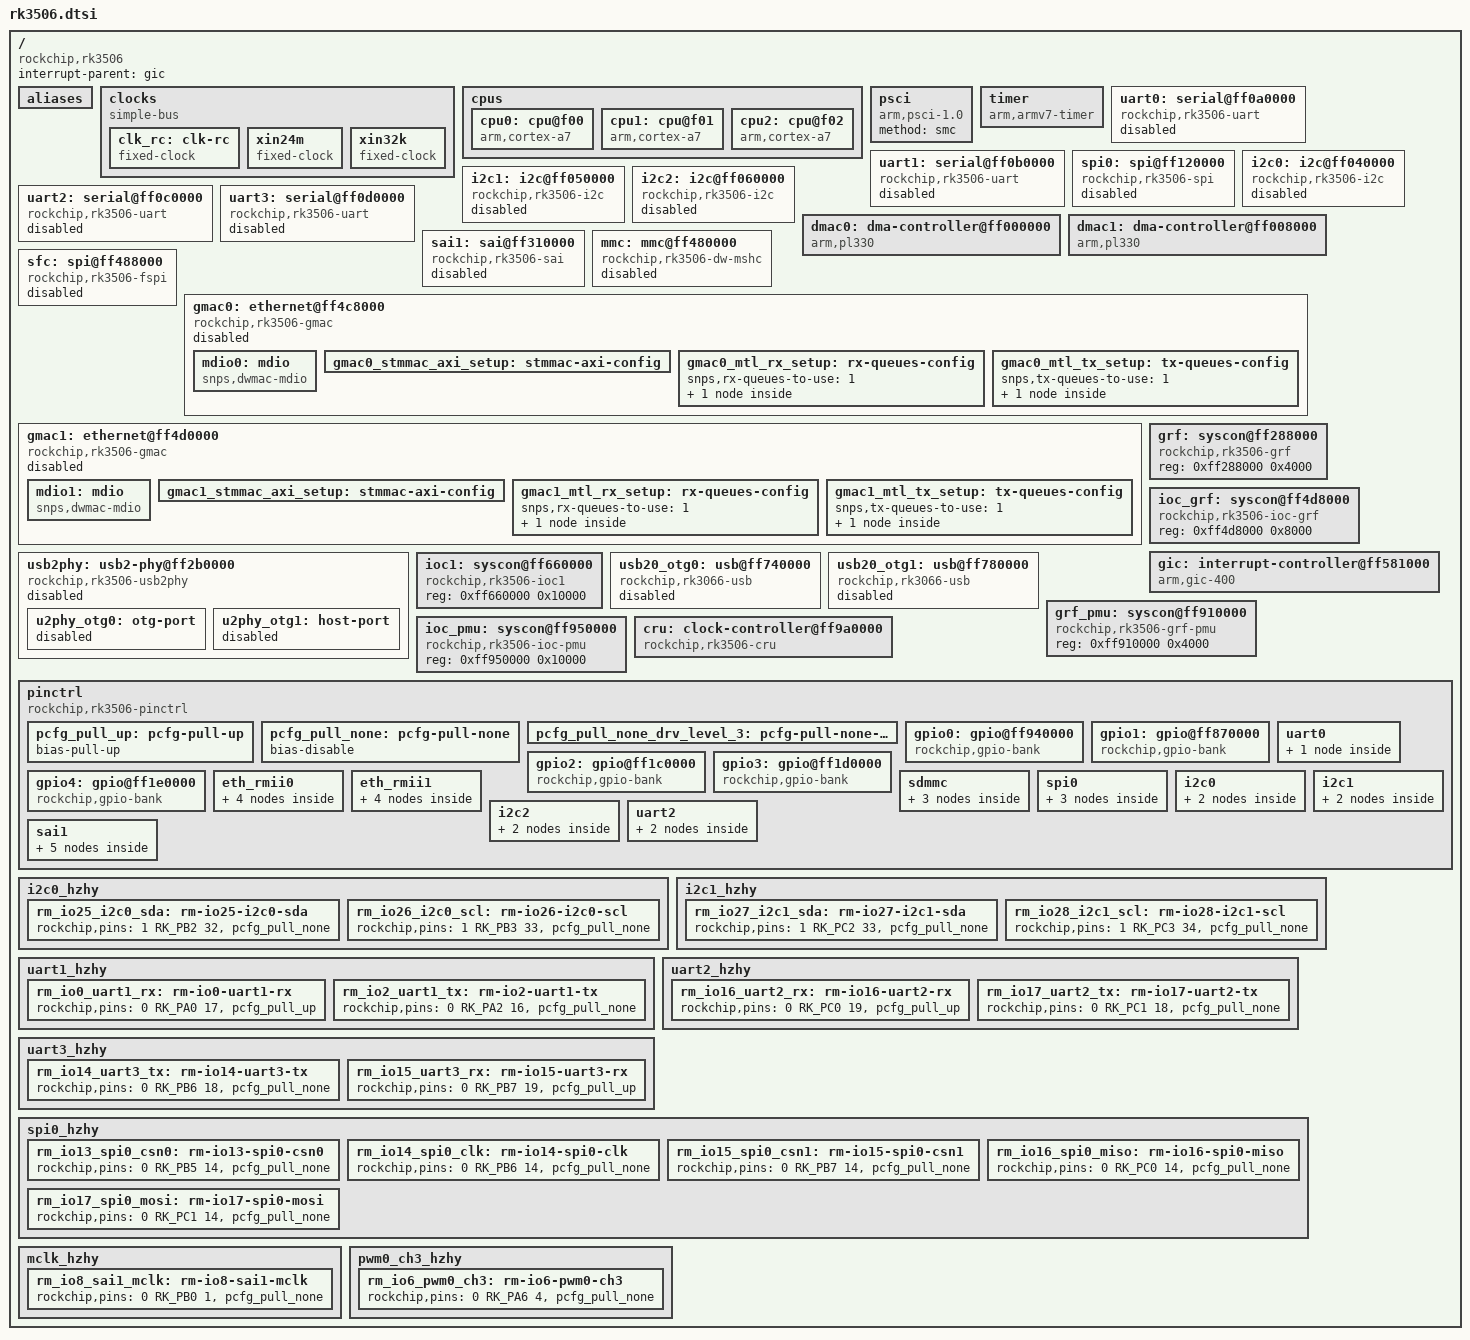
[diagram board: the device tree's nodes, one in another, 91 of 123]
// SPDX-License-Identifier: (GPL-2.0+ OR MIT)
/*
 * (C) Copyright 2023 Rockchip Electronics Co., Ltd.
 *
 * Minimal RK3506 SoC dtsi for mainline Linux bring-up.
 * Ported/reduced from the ATK vendor SDK rk3502.dtsi. Nodes needed to boot +
 * reach the early UART console: clocks, cru, grf, ioc syscons, gic, arch timer,
 * psci, cpus, pinctrl (all 5 gpio banks) + uart0.
 * + sfc (SPI flash controller) — drives the W25N04KV SPI-NAND, needed for a
 *   persistent rootfs on NAND. Uses the mainline `rockchip,sfc` binding (the
 *   same node proven on the U-Boot side); vendor BSP instead uses a private
 *   `fspi` driver — we stay mainline. The mainline rockchip_sfc.c now ports
 *   the vendor delay-line tuning, so the SFC runs at full speed. See notes/10
 *   + BLOBS.md.
 * Other peripherals (i2c/spi/pwm/sai/mmc/usb/display/io-domains) still deferred.
 */

#include <dt-bindings/clock/rockchip,rk3506-cru.h>
#include <dt-bindings/reset/rockchip,rk3506-cru.h>
#include <dt-bindings/gpio/gpio.h>
#include <dt-bindings/interrupt-controller/irq.h>
#include <dt-bindings/interrupt-controller/arm-gic.h>
#include <dt-bindings/pinctrl/rockchip.h>

/ {
	#address-cells = <1>;
	#size-cells = <1>;

	compatible = "rockchip,rk3506";

	interrupt-parent = <&gic>;

	aliases {
		gpio0 = &gpio0;
		gpio1 = &gpio1;
		gpio2 = &gpio2;
		gpio3 = &gpio3;
		gpio4 = &gpio4;
		serial0 = &uart0;
		serial2 = &uart2;
		ethernet0 = &gmac0;
		ethernet1 = &gmac1;
		i2c0 = &i2c0;
		i2c1 = &i2c1;
		i2c2 = &i2c2;
	};

	clocks {
		compatible = "simple-bus";
		#address-cells = <1>;
		#size-cells = <1>;
		ranges;

		clk_rc: clk-rc {
			compatible = "fixed-clock";
			#clock-cells = <0>;
			clock-frequency = <400000>;
			clock-output-names = "clk_rc";
		};

		xin24m: xin24m {
			compatible = "fixed-clock";
			#clock-cells = <0>;
			clock-frequency = <24000000>;
			clock-output-names = "xin24m";
		};

		xin32k: xin32k {
			compatible = "fixed-clock";
			#clock-cells = <0>;
			clock-frequency = <32768>;
			clock-output-names = "xin32k";
		};
	};

	cpus {
		#address-cells = <1>;
		#size-cells = <0>;

		cpu0: cpu@f00 {
			device_type = "cpu";
			compatible = "arm,cortex-a7";
			reg = <0xf00>;
			enable-method = "psci";
			clocks = <&cru ARMCLK>;
		};

		cpu1: cpu@f01 {
			device_type = "cpu";
			compatible = "arm,cortex-a7";
			reg = <0xf01>;
			enable-method = "psci";
			clocks = <&cru ARMCLK>;
		};

		cpu2: cpu@f02 {
			device_type = "cpu";
			compatible = "arm,cortex-a7";
			reg = <0xf02>;
			enable-method = "psci";
			clocks = <&cru ARMCLK>;
		};
	};

	psci {
		compatible = "arm,psci-1.0";
		method = "smc";
	};

	timer {
		compatible = "arm,armv7-timer";
		interrupts = <GIC_PPI 13 (GIC_CPU_MASK_SIMPLE(3) | IRQ_TYPE_LEVEL_HIGH)>,
			     <GIC_PPI 14 (GIC_CPU_MASK_SIMPLE(3) | IRQ_TYPE_LEVEL_HIGH)>,
			     <GIC_PPI 11 (GIC_CPU_MASK_SIMPLE(3) | IRQ_TYPE_LEVEL_HIGH)>,
			     <GIC_PPI 10 (GIC_CPU_MASK_SIMPLE(3) | IRQ_TYPE_LEVEL_HIGH)>;
		clock-frequency = <24000000>;
	};

	uart0: serial@ff0a0000 {
		compatible = "rockchip,rk3506-uart", "snps,dw-apb-uart";
		reg = <0xff0a0000 0x100>;
		interrupts = <GIC_SPI 34 IRQ_TYPE_LEVEL_HIGH>;
		reg-shift = <2>;
		reg-io-width = <4>;
		clocks = <&cru SCLK_UART0>, <&cru PCLK_UART0>;
		clock-names = "baudclk", "apb_pclk";
		pinctrl-names = "default";
		pinctrl-0 = <&uart0_xfer_pins>;
		status = "disabled";
	};
	uart1: serial@ff0b0000 {
		compatible = "rockchip,rk3506-uart", "snps,dw-apb-uart";
		reg = <0xff0b0000 0x100>;
		interrupts = <GIC_SPI 35 IRQ_TYPE_LEVEL_HIGH>;
		reg-shift = <2>;
		reg-io-width = <4>;
		clocks = <&cru SCLK_UART1>, <&cru PCLK_UART1>;
		clock-names = "baudclk", "apb_pclk";
		pinctrl-names = "default";
		status = "disabled";
	};


	spi0: spi@ff120000 {
		compatible = "rockchip,rk3506-spi", "rockchip,rk3066-spi";
		reg = <0xff120000 0x1000>;
		interrupts = <GIC_SPI 43 IRQ_TYPE_LEVEL_HIGH>;
		#address-cells = <1>;
		#size-cells = <0>;
		clocks = <&cru CLK_SPI0>, <&cru PCLK_SPI0>;
		clock-names = "spiclk", "apb_pclk";
		num-cs = <2>;
		pinctrl-names = "default";
		pinctrl-0 = <&spi0_csn0_pins &spi0_csn1_pins &spi0_clk_pins>;
		status = "disabled";
	};

	i2c0: i2c@ff040000 {
		compatible = "rockchip,rk3506-i2c", "rockchip,rk3399-i2c";
		reg = <0xff040000 0x1000>;
		interrupts = <GIC_SPI 40 IRQ_TYPE_LEVEL_HIGH>;
		#address-cells = <1>;
		#size-cells = <0>;
		clocks = <&cru CLK_I2C0>, <&cru PCLK_I2C0>;
		clock-names = "i2c", "pclk";
		status = "disabled";
	};

	i2c1: i2c@ff050000 {
		compatible = "rockchip,rk3506-i2c", "rockchip,rk3399-i2c";
		reg = <0xff050000 0x1000>;
		interrupts = <GIC_SPI 41 IRQ_TYPE_LEVEL_HIGH>;
		#address-cells = <1>;
		#size-cells = <0>;
		clocks = <&cru CLK_I2C1>, <&cru PCLK_I2C1>;
		clock-names = "i2c", "pclk";
		status = "disabled";
	};

	i2c2: i2c@ff060000 {
		compatible = "rockchip,rk3506-i2c", "rockchip,rk3399-i2c";
		reg = <0xff060000 0x1000>;
		interrupts = <GIC_SPI 42 IRQ_TYPE_LEVEL_HIGH>;
		#address-cells = <1>;
		#size-cells = <0>;
		clocks = <&cru CLK_I2C2>, <&cru PCLK_I2C2>;
		clock-names = "i2c", "pclk";
		status = "disabled";
	};

	uart2: serial@ff0c0000 {
		compatible = "rockchip,rk3506-uart", "snps,dw-apb-uart";
		reg = <0xff0c0000 0x100>;
		interrupts = <GIC_SPI 36 IRQ_TYPE_LEVEL_HIGH>;
		reg-shift = <2>;
		reg-io-width = <4>;
		clocks = <&cru SCLK_UART2>, <&cru PCLK_UART2>;
		clock-names = "baudclk", "apb_pclk";
		status = "disabled";
	};

	uart3: serial@ff0d0000 {
		compatible = "rockchip,rk3506-uart", "snps,dw-apb-uart";
		reg = <0xff0d0000 0x100>;
		interrupts = <GIC_SPI 37 IRQ_TYPE_LEVEL_HIGH>;
		reg-shift = <2>;
		reg-io-width = <4>;
		clocks = <&cru SCLK_UART3>, <&cru PCLK_UART3>;
		clock-names = "baudclk", "apb_pclk";
		pinctrl-names = "default";
		status = "disabled";
	};

	dmac0: dma-controller@ff000000 {
		compatible = "arm,pl330", "arm,primecell";
		reg = <0xff000000 0x4000>;
		interrupts = <GIC_SPI 116 IRQ_TYPE_LEVEL_HIGH>,
			     <GIC_SPI 117 IRQ_TYPE_LEVEL_HIGH>;
		clocks = <&cru ACLK_DMAC0>;
		clock-names = "apb_pclk";
		#dma-cells = <5>;
		arm,pl330-periph-burst;
	};

	dmac1: dma-controller@ff008000 {
		compatible = "arm,pl330", "arm,primecell";
		reg = <0xff008000 0x4000>;
		interrupts = <GIC_SPI 118 IRQ_TYPE_LEVEL_HIGH>,
			     <GIC_SPI 119 IRQ_TYPE_LEVEL_HIGH>;
		clocks = <&cru ACLK_DMAC1>;
		clock-names = "apb_pclk";
		#dma-cells = <5>;
		arm,pl330-periph-burst;
	};

	sai1: sai@ff310000 {
		compatible = "rockchip,rk3506-sai", "rockchip,sai-v1";
		reg = <0xff310000 0x1000>;
		interrupts = <GIC_SPI 51 IRQ_TYPE_LEVEL_HIGH>;
		clocks = <&cru MCLK_SAI1>, <&cru HCLK_SAI1>;
		clock-names = "mclk", "hclk";
		/* 5-cell: <dmac chan mux_reg mux_val mux_reg mux_val> — the GRF
		 * DMA request crossbar (programmed by the pl330 dmamux patch). */
		dmas = <&dmac1 3  0xff2880a4 0x04000000 0x0 0x0>,
		       <&dmac1 2  0xff2880a4 0x02000000 0x0 0x0>;
		dma-names = "tx", "rx";
		resets = <&cru SRST_M_SAI1>, <&cru SRST_H_SAI1>;
		reset-names = "m", "h";
		#sound-dai-cells = <0>;
		pinctrl-names = "default";
		/* sdo0 only (stereo) — sdo1/2/3 would clash with i2c0 on PB5/6/7. */
		pinctrl-0 = <&sai1_lrck_pins &sai1_sclk_pins &sai1_sdi_pins
			     &sai1_sdo0_pins &sai1_mclk_pins>;
		status = "disabled";
	};

	mmc: mmc@ff480000 {
		compatible = "rockchip,rk3506-dw-mshc", "rockchip,rk3288-dw-mshc";
		reg = <0xff480000 0x4000>;
		interrupts = <GIC_SPI 86 IRQ_TYPE_LEVEL_HIGH>;
		max-frequency = <150000000>;
		bus-width = <4>;
		clocks = <&cru HCLK_SDMMC>, <&cru CCLK_SRC_SDMMC>;
		clock-names = "biu", "ciu";
		fifo-depth = <0x100>;
		resets = <&cru SRST_H_SDMMC>;
		reset-names = "reset";
		status = "disabled";
	};

	sfc: spi@ff488000 {
		compatible = "rockchip,rk3506-fspi", "rockchip,sfc";
		reg = <0xff488000 0x4000>;
		interrupts = <GIC_SPI 85 IRQ_TYPE_LEVEL_HIGH>;
		clocks = <&cru SCLK_FSPI>, <&cru HCLK_FSPI>;
		clock-names = "clk_sfc", "hclk_sfc";
		rockchip,grf = <&grf_pmu>;	/* power-good gate (GRF_PMU+0x100 bit0); needed for reliable writes */
		/* No rockchip,sfc-no-dma → use DMA (aligns vendor rk3506 fspi, which has no no-dma).
		 * The earlier no-dma was a stale debug workaround (nand-ecc-debug-handoff, "rule out
		 * DMA/cache"); "DMA reads corrupt" was never proven. NB: DMA does NOT fix the
		 * rootfs PEB-3/4 -74 — that's loader marginal write (~8flips, read-nondeterministic),
		 * handled by ubiprog (notes/27). DMA kept purely for vendor parity. */
		rockchip,max-dll = <0x17F>;	/* RK3506 SFC is VER_5; cap DLL cell scan (vendor value) */
		#address-cells = <1>;
		#size-cells = <0>;
		status = "disabled";
	};

	gmac0: ethernet@ff4c8000 {
		compatible = "rockchip,rk3506-gmac", "snps,dwmac-4.20a";
		reg = <0xff4c8000 0x2000>;
		interrupts = <GIC_SPI 66 IRQ_TYPE_LEVEL_HIGH>,
			     <GIC_SPI 69 IRQ_TYPE_LEVEL_HIGH>;
		interrupt-names = "macirq", "eth_wake_irq";
		rockchip,grf = <&grf>;
		clocks = <&cru CLK_MAC0>, <&cru CLK_MAC0_PTP>,
			 <&cru PCLK_MAC0>, <&cru ACLK_MAC0>;
		clock-names = "stmmaceth", "ptp_ref",
			      "pclk_mac", "aclk_mac";
		resets = <&cru SRST_A_MAC0>;
		reset-names = "stmmaceth";

		assigned-clocks = <&cru CLK_MAC0_PTP>;
		assigned-clock-rates = <62500000>;

		snps,mixed-burst;
		snps,tso;

		snps,axi-config = <&gmac0_stmmac_axi_setup>;
		snps,mtl-rx-config = <&gmac0_mtl_rx_setup>;
		snps,mtl-tx-config = <&gmac0_mtl_tx_setup>;

		phy-mode = "rmii";
		status = "disabled";

		mdio0: mdio {
			compatible = "snps,dwmac-mdio";
			#address-cells = <0x1>;
			#size-cells = <0x0>;
		};

		gmac0_stmmac_axi_setup: stmmac-axi-config {
			snps,wr_osr_lmt = <4>;
			snps,rd_osr_lmt = <8>;
			snps,blen = <0 0 0 0 16 8 4>;
		};

		gmac0_mtl_rx_setup: rx-queues-config {
			snps,rx-queues-to-use = <1>;
			queue0 {
				status = "okay";
			};
		};

		gmac0_mtl_tx_setup: tx-queues-config {
			snps,tx-queues-to-use = <1>;
			queue0 {
				status = "okay";
			};
		};
	};

	gmac1: ethernet@ff4d0000 {
		compatible = "rockchip,rk3506-gmac", "snps,dwmac-4.20a";
		reg = <0xff4d0000 0x2000>;
		interrupts = <GIC_SPI 70 IRQ_TYPE_LEVEL_HIGH>,
			     <GIC_SPI 73 IRQ_TYPE_LEVEL_HIGH>;
		interrupt-names = "macirq", "eth_wake_irq";
		rockchip,grf = <&grf>;
		clocks = <&cru CLK_MAC1>, <&cru CLK_MAC1_PTP>,
			 <&cru PCLK_MAC1>, <&cru ACLK_MAC1>;
		clock-names = "stmmaceth", "ptp_ref",
			      "pclk_mac", "aclk_mac";
		resets = <&cru SRST_A_MAC1>;
		reset-names = "stmmaceth";

		assigned-clocks = <&cru CLK_MAC1_PTP>;
		assigned-clock-rates = <62500000>;

		snps,mixed-burst;
		snps,tso;

		snps,axi-config = <&gmac1_stmmac_axi_setup>;
		snps,mtl-rx-config = <&gmac1_mtl_rx_setup>;
		snps,mtl-tx-config = <&gmac1_mtl_tx_setup>;

		phy-mode = "rmii";
		status = "disabled";

		mdio1: mdio {
			compatible = "snps,dwmac-mdio";
			#address-cells = <0x1>;
			#size-cells = <0x0>;
		};

		gmac1_stmmac_axi_setup: stmmac-axi-config {
			snps,wr_osr_lmt = <4>;
			snps,rd_osr_lmt = <8>;
			snps,blen = <0 0 0 0 16 8 4>;
		};

		gmac1_mtl_rx_setup: rx-queues-config {
			snps,rx-queues-to-use = <1>;
			queue0 {
				status = "okay";
			};
		};

		gmac1_mtl_tx_setup: tx-queues-config {
			snps,tx-queues-to-use = <1>;
			queue0 {
				status = "okay";
			};
		};
	};

	grf: syscon@ff288000 {
		compatible = "rockchip,rk3506-grf", "syscon", "simple-mfd";
		reg = <0xff288000 0x4000>;
	};

	usb2phy: usb2-phy@ff2b0000 {
		compatible = "rockchip,rk3506-usb2phy";
		reg = <0xff2b0000 0x8000>;
		clocks = <&cru CLK_REF_USBPHY_TOP>, <&cru PCLK_USBPHY>;
		clock-names = "phyclk", "apb_pclk";
		rockchip,usbgrf = <&grf>;
		status = "disabled";

		u2phy_otg0: otg-port {
			#phy-cells = <0>;
			interrupts = <GIC_SPI 75 IRQ_TYPE_LEVEL_HIGH>,
				     <GIC_SPI 76 IRQ_TYPE_LEVEL_HIGH>,
				     <GIC_SPI 77 IRQ_TYPE_LEVEL_HIGH>;
			interrupt-names = "otg-bvalid", "otg-id", "linestate";
			status = "disabled";
		};

		u2phy_otg1: host-port {
			#phy-cells = <0>;
			interrupts = <GIC_SPI 80 IRQ_TYPE_LEVEL_HIGH>,
				     <GIC_SPI 81 IRQ_TYPE_LEVEL_HIGH>,
				     <GIC_SPI 82 IRQ_TYPE_LEVEL_HIGH>;
			interrupt-names = "otg-bvalid", "otg-id", "linestate";
			status = "disabled";
		};
	};

	ioc_grf: syscon@ff4d8000 {
		compatible = "rockchip,rk3506-ioc-grf", "syscon";
		reg = <0xff4d8000 0x8000>;
	};

	gic: interrupt-controller@ff581000 {
		compatible = "arm,gic-400";
		reg = <0xff581000 0x1000>,
		      <0xff582000 0x2000>,
		      <0xff584000 0x2000>,
		      <0xff586000 0x2000>;
		interrupts = <GIC_PPI 9 IRQ_TYPE_LEVEL_HIGH>;
		#interrupt-cells = <3>;
		interrupt-controller;
		#address-cells = <0>;
	};

	ioc1: syscon@ff660000 {
		compatible = "rockchip,rk3506-ioc1", "syscon";
		reg = <0xff660000 0x10000>;
	};

	usb20_otg0: usb@ff740000 {
		compatible = "rockchip,rk3066-usb", "snps,dwc2";
		reg = <0xff740000 0x40000>;
		interrupts = <GIC_SPI 74 IRQ_TYPE_LEVEL_HIGH>;
		clocks = <&cru HCLK_USBOTG0>, <&cru HCLK_USBOTG0_PMU>,
			 <&cru CLK_USBOTG0_ADP>;
		clock-names = "otg", "pmu", "adp";
		dr_mode = "otg";
		phys = <&u2phy_otg0>;
		phy-names = "usb2-phy";
		g-np-tx-fifo-size = <16>;
		g-rx-fifo-size = <280>;
		g-tx-fifo-size = <256 128 128 64 32 16>;
		status = "disabled";
	};

	usb20_otg1: usb@ff780000 {
		compatible = "rockchip,rk3066-usb", "snps,dwc2";
		reg = <0xff780000 0x40000>;
		interrupts = <GIC_SPI 79 IRQ_TYPE_LEVEL_HIGH>;
		clocks = <&cru HCLK_USBOTG1>, <&cru HCLK_USBOTG1_PMU>,
			 <&cru CLK_USBOTG1_ADP>;
		clock-names = "otg", "pmu", "adp";
		dr_mode = "otg";
		phys = <&u2phy_otg1>;
		phy-names = "usb2-phy";
		g-np-tx-fifo-size = <16>;
		g-rx-fifo-size = <280>;
		g-tx-fifo-size = <256 128 128 64 32 16>;
		status = "disabled";
	};

	grf_pmu: syscon@ff910000 {
		compatible = "rockchip,rk3506-grf-pmu", "syscon", "simple-mfd";
		reg = <0xff910000 0x4000>;
	};

	ioc_pmu: syscon@ff950000 {
		compatible = "rockchip,rk3506-ioc-pmu", "syscon";
		reg = <0xff950000 0x10000>;
	};

	cru: clock-controller@ff9a0000 {
		compatible = "rockchip,rk3506-cru";
		reg = <0xff9a0000 0x20000>;
		rockchip,grf = <&grf>;
		#clock-cells = <1>;
		#reset-cells = <1>;

		assigned-clocks =
			<&cru CLK_32K_FRAC>,
			<&cru CLK_FRAC_UART_MATRIX0>,
			<&cru CLK_FRAC_UART_MATRIX1>;
		assigned-clock-rates =
			<32768>,
			<96000000>,
			<128000000>;
	};

	pinctrl: pinctrl {
		compatible = "rockchip,rk3506-pinctrl";
		rockchip,grf = <&ioc_grf>;
		rockchip,ioc1 = <&ioc1>;
		rockchip,pmu = <&ioc_pmu>;
		rockchip,rmio = <&grf_pmu>;	/* RMIO crossbar (rk3506 rm_io pads); see pinctrl RMIO patch */
		#address-cells = <1>;
		#size-cells = <1>;
		ranges;

		pcfg_pull_up: pcfg-pull-up {
			bias-pull-up;
		};

		pcfg_pull_none: pcfg-pull-none {
			bias-disable;
		};

		pcfg_pull_none_drv_level_3: pcfg-pull-none-drv-level-3 {
			bias-disable;
			drive-strength = <3>;
		};

		gpio0: gpio@ff940000 {
			compatible = "rockchip,gpio-bank";
			reg = <0xff940000 0x200>;
			interrupts = <GIC_SPI 0 IRQ_TYPE_LEVEL_HIGH>,
				     <GIC_SPI 1 IRQ_TYPE_LEVEL_HIGH>,
				     <GIC_SPI 2 IRQ_TYPE_LEVEL_HIGH>,
				     <GIC_SPI 3 IRQ_TYPE_LEVEL_HIGH>;
			clocks = <&cru PCLK_GPIO0>, <&cru DBCLK_GPIO0>;

			gpio-controller;
			#gpio-cells = <2>;
			gpio-ranges = <&pinctrl 0 0 32>;
			interrupt-controller;
			#interrupt-cells = <2>;
		};

		gpio1: gpio@ff870000 {
			compatible = "rockchip,gpio-bank";
			reg = <0xff870000 0x200>;
			interrupts = <GIC_SPI 4 IRQ_TYPE_LEVEL_HIGH>,
				     <GIC_SPI 5 IRQ_TYPE_LEVEL_HIGH>,
				     <GIC_SPI 6 IRQ_TYPE_LEVEL_HIGH>,
				     <GIC_SPI 7 IRQ_TYPE_LEVEL_HIGH>;

			clocks = <&cru PCLK_GPIO1>, <&cru DBCLK_GPIO1>;

			gpio-controller;
			#gpio-cells = <2>;
			gpio-ranges = <&pinctrl 0 32 32>;
			interrupt-controller;
			#interrupt-cells = <2>;
		};

		gpio2: gpio@ff1c0000 {
			compatible = "rockchip,gpio-bank";
			reg = <0xff1c0000 0x200>;
			interrupts = <GIC_SPI 8 IRQ_TYPE_LEVEL_HIGH>,
				     <GIC_SPI 9 IRQ_TYPE_LEVEL_HIGH>,
				     <GIC_SPI 10 IRQ_TYPE_LEVEL_HIGH>,
				     <GIC_SPI 11 IRQ_TYPE_LEVEL_HIGH>;
			clocks = <&cru PCLK_GPIO2>, <&cru DBCLK_GPIO2>;

			gpio-controller;
			#gpio-cells = <2>;
			gpio-ranges = <&pinctrl 0 64 32>;
			interrupt-controller;
			#interrupt-cells = <2>;
		};

		gpio3: gpio@ff1d0000 {
			compatible = "rockchip,gpio-bank";
			reg = <0xff1d0000 0x200>;
			interrupts = <GIC_SPI 12 IRQ_TYPE_LEVEL_HIGH>,
				     <GIC_SPI 13 IRQ_TYPE_LEVEL_HIGH>,
				     <GIC_SPI 14 IRQ_TYPE_LEVEL_HIGH>,
				     <GIC_SPI 15 IRQ_TYPE_LEVEL_HIGH>;
			clocks = <&cru PCLK_GPIO3>, <&cru DBCLK_GPIO3>;

			gpio-controller;
			#gpio-cells = <2>;
			gpio-ranges = <&pinctrl 0 96 32>;
			interrupt-controller;
			#interrupt-cells = <2>;
		};

		gpio4: gpio@ff1e0000 {
			compatible = "rockchip,gpio-bank";
			reg = <0xff1e0000 0x200>;
			interrupts = <GIC_SPI 16 IRQ_TYPE_LEVEL_HIGH>,
				     <GIC_SPI 17 IRQ_TYPE_LEVEL_HIGH>,
				     <GIC_SPI 18 IRQ_TYPE_LEVEL_HIGH>,
				     <GIC_SPI 19 IRQ_TYPE_LEVEL_HIGH>;
			clocks = <&cru PCLK_GPIO4>, <&cru DBCLK_GPIO4>;

			gpio-controller;
			#gpio-cells = <2>;
			gpio-ranges = <&pinctrl 0 128 32>;
			interrupt-controller;
			#interrupt-cells = <2>;
		};

		uart0 {
			uart0_xfer_pins: uart0-xfer-pins {
				rockchip,pins =
					/* uart0_rx */ <0 RK_PC7 1 &pcfg_pull_up>,
					/* uart0_tx */ <0 RK_PC6 1 &pcfg_pull_up>;
			};
		};

		eth_rmii0 {
			/omit-if-no-ref/
			eth_rmii0_miim_pins: eth-rmii0-miim-pins {
				rockchip,pins =
					/* eth_rmii0_mdc */ <2 RK_PB6 1 &pcfg_pull_none>,
					/* eth_rmii0_mdio */ <2 RK_PB7 1 &pcfg_pull_none>;
			};

			/omit-if-no-ref/
			eth_rmii0_rx_bus2_pins: eth-rmii0-rx-bus2-pins {
				rockchip,pins =
					/* eth_rmii0_rxd0 */ <2 RK_PB0 1 &pcfg_pull_none>,
					/* eth_rmii0_rxd1 */ <2 RK_PB1 1 &pcfg_pull_none>,
					/* eth_rmii0_rxdvcrs */ <2 RK_PC0 1 &pcfg_pull_none>;
			};

			/omit-if-no-ref/
			eth_rmii0_tx_bus2_pins: eth-rmii0-tx-bus2-pins {
				rockchip,pins =
					/* eth_rmii0_txd0 */ <2 RK_PB3 1 &pcfg_pull_none>,
					/* eth_rmii0_txd1 */ <2 RK_PB4 1 &pcfg_pull_none>,
					/* eth_rmii0_txen */ <2 RK_PB5 1 &pcfg_pull_none>;
			};

			/omit-if-no-ref/
			eth_rmii0_clk_pins: eth-rmii0-clk-pins {
				rockchip,pins =
					/* eth_rmii0_clk */ <2 RK_PB2 1 &pcfg_pull_none>;
			};
		};

		eth_rmii1 {
			/omit-if-no-ref/
			eth_rmii1_miim_pins: eth-rmii1-miim-pins {
				rockchip,pins =
					/* eth_rmii1_mdc */ <3 RK_PB4 2 &pcfg_pull_none>,
					/* eth_rmii1_mdio */ <3 RK_PB5 2 &pcfg_pull_none>;
			};

			/omit-if-no-ref/
			eth_rmii1_rx_bus2_pins: eth-rmii1-rx-bus2-pins {
				rockchip,pins =
					/* eth_rmii1_rxd0 */ <3 RK_PA6 2 &pcfg_pull_none>,
					/* eth_rmii1_rxd1 */ <3 RK_PA7 2 &pcfg_pull_none>,
					/* eth_rmii1_rxdvcrs */ <3 RK_PB6 2 &pcfg_pull_none>;
			};

			/omit-if-no-ref/
			eth_rmii1_tx_bus2_pins: eth-rmii1-tx-bus2-pins {
				rockchip,pins =
					/* eth_rmii1_txd0 */ <3 RK_PB1 2 &pcfg_pull_none>,
					/* eth_rmii1_txd1 */ <3 RK_PB2 2 &pcfg_pull_none>,
					/* eth_rmii1_txen */ <3 RK_PB3 2 &pcfg_pull_none>;
			};

			/omit-if-no-ref/
			eth_rmii1_clk_pins: eth-rmii1-clk-pins {
				rockchip,pins =
					/* eth_rmii1_clk */ <3 RK_PB0 2 &pcfg_pull_none>;
			};
		};

		sdmmc {
			/omit-if-no-ref/
			sdmmc_bus4_pins: sdmmc-bus4-pins {
				rockchip,pins =
					/* sdmmc_d0 */ <3 RK_PA2 1 &pcfg_pull_up>,
					/* sdmmc_d1 */ <3 RK_PA3 1 &pcfg_pull_up>,
					/* sdmmc_d2 */ <3 RK_PA4 1 &pcfg_pull_up>,
					/* sdmmc_d3 */ <3 RK_PA5 1 &pcfg_pull_up>;
			};

			/omit-if-no-ref/
			sdmmc_clk_pins: sdmmc-clk-pins {
				rockchip,pins =
					/* sdmmc_clk */ <3 RK_PA0 1 &pcfg_pull_none>;
			};

			/omit-if-no-ref/
			sdmmc_cmd_pins: sdmmc-cmd-pins {
				rockchip,pins =
					/* sdmmc_cmd */ <3 RK_PA1 1 &pcfg_pull_up>;
			};
		};

		spi0 {
			/omit-if-no-ref/
			spi0_clk_pins: spi0-clk-pins {
				rockchip,pins =
					/* spi0_clk */ <0 RK_PC0 2 &pcfg_pull_none_drv_level_3>,
					/* spi0_miso */ <0 RK_PC2 2 &pcfg_pull_none_drv_level_3>,
					/* spi0_mosi */ <0 RK_PC1 2 &pcfg_pull_none_drv_level_3>;
			};

			/omit-if-no-ref/
			spi0_csn0_pins: spi0-csn0-pins {
				rockchip,pins =
					/* spi0_csn0 */ <0 RK_PC3 2 &pcfg_pull_none_drv_level_3>;
			};

			/omit-if-no-ref/
			spi0_csn1_pins: spi0-csn1-pins {
				rockchip,pins =
					/* spi0_csn1 */ <0 RK_PB7 2 &pcfg_pull_none_drv_level_3>;
			};
		};

		/* RMIO crossbar groups (mux values > iomux width route via grf_pmu).
		 * Reduced from vendor rk3506-pinctrl-rmio.dtsi to the pads the AES
		 * board actually wires: i2c0 on rm_io13/14, i2c1 on rm_io24/25,
		 * i2c2 on rm_io4/5, uart2 on rm_io26/27. */
		i2c0 {
			/omit-if-no-ref/
			rm_io13_i2c0_scl: rm-io13-i2c0-scl {
				rockchip,pins = <0 RK_PB5 30 &pcfg_pull_none>;
			};
			/omit-if-no-ref/
			rm_io14_i2c0_sda: rm-io14-i2c0-sda {
				rockchip,pins = <0 RK_PB6 31 &pcfg_pull_none>;
			};
		};

		i2c1 {
			/omit-if-no-ref/
			rm_io24_i2c1_scl: rm-io24-i2c1-scl {
				rockchip,pins = <1 RK_PB1 32 &pcfg_pull_none>;
			};
			/omit-if-no-ref/
			rm_io25_i2c1_sda: rm-io25-i2c1-sda {
				rockchip,pins = <1 RK_PB2 33 &pcfg_pull_none>;
			};
		};

		i2c2 {
			/omit-if-no-ref/
			rm_io4_i2c2_scl: rm-io4-i2c2-scl {
				rockchip,pins = <0 RK_PA4 34 &pcfg_pull_none>;
			};
			/omit-if-no-ref/
			rm_io5_i2c2_sda: rm-io5-i2c2-sda {
				rockchip,pins = <0 RK_PA5 35 &pcfg_pull_none>;
			};
		};

		uart2 {
			/omit-if-no-ref/
			rm_io26_uart2_tx: rm-io26-uart2-tx {
				rockchip,pins = <1 RK_PB3 18 &pcfg_pull_none>;
			};
			/omit-if-no-ref/
			rm_io27_uart2_rx: rm-io27-uart2-rx {
				rockchip,pins = <1 RK_PC2 19 &pcfg_pull_up>;
			};
		};

		sai1 {
			/omit-if-no-ref/
			sai1_mclk_pins: sai1-mclk-pins {
				rockchip,pins = <0 RK_PB0 1 &pcfg_pull_none>;
			};
			/omit-if-no-ref/
			sai1_sclk_pins: sai1-sclk-pins {
				rockchip,pins = <0 RK_PB1 1 &pcfg_pull_none>;
			};
			/omit-if-no-ref/
			sai1_lrck_pins: sai1-lrck-pins {
				rockchip,pins = <0 RK_PB2 1 &pcfg_pull_none>;
			};
			/omit-if-no-ref/
			sai1_sdi_pins: sai1-sdi-pins {
				rockchip,pins = <0 RK_PB3 1 &pcfg_pull_none>;
			};
			/omit-if-no-ref/
			sai1_sdo0_pins: sai1-sdo0-pins {
				rockchip,pins = <0 RK_PB4 1 &pcfg_pull_none>;
			};
		};
	};
		/*
		 * HZHY MiniEVM RMIO pin groups — additional mappings beyond the
		 * AES reference set. /omit-if-no-ref/ guarded; no conflict with
		 * existing groups (different pad/function combinations).
		 */
		i2c0_hzhy {
			/omit-if-no-ref/
			rm_io25_i2c0_sda: rm-io25-i2c0-sda {
				rockchip,pins = <1 RK_PB2 32 &pcfg_pull_none>;
			};
			/omit-if-no-ref/
			rm_io26_i2c0_scl: rm-io26-i2c0-scl {
				rockchip,pins = <1 RK_PB3 33 &pcfg_pull_none>;
			};
		};
		i2c1_hzhy {
			/omit-if-no-ref/
			rm_io27_i2c1_sda: rm-io27-i2c1-sda {
				rockchip,pins = <1 RK_PC2 33 &pcfg_pull_none>;
			};
			/omit-if-no-ref/
			rm_io28_i2c1_scl: rm-io28-i2c1-scl {
				rockchip,pins = <1 RK_PC3 34 &pcfg_pull_none>;
			};
		};
		uart1_hzhy {
			/omit-if-no-ref/
			rm_io0_uart1_rx: rm-io0-uart1-rx {
				rockchip,pins = <0 RK_PA0 17 &pcfg_pull_up>;
			};
			/omit-if-no-ref/
			rm_io2_uart1_tx: rm-io2-uart1-tx {
				rockchip,pins = <0 RK_PA2 16 &pcfg_pull_none>;
			};
		};
		uart2_hzhy {
			/omit-if-no-ref/
			rm_io16_uart2_rx: rm-io16-uart2-rx {
				rockchip,pins = <0 RK_PC0 19 &pcfg_pull_up>;
			};
			/omit-if-no-ref/
			rm_io17_uart2_tx: rm-io17-uart2-tx {
				rockchip,pins = <0 RK_PC1 18 &pcfg_pull_none>;
			};
		};
		uart3_hzhy {
			/omit-if-no-ref/
			rm_io14_uart3_tx: rm-io14-uart3-tx {
				rockchip,pins = <0 RK_PB6 18 &pcfg_pull_none>;
			};
			/omit-if-no-ref/
			rm_io15_uart3_rx: rm-io15-uart3-rx {
				rockchip,pins = <0 RK_PB7 19 &pcfg_pull_up>;
			};
		};
		spi0_hzhy {
			/omit-if-no-ref/
			rm_io13_spi0_csn0: rm-io13-spi0-csn0 {
				rockchip,pins = <0 RK_PB5 14 &pcfg_pull_none>;
			};
			/omit-if-no-ref/
			rm_io14_spi0_clk: rm-io14-spi0-clk {
				rockchip,pins = <0 RK_PB6 14 &pcfg_pull_none>;
			};
			/omit-if-no-ref/
			rm_io15_spi0_csn1: rm-io15-spi0-csn1 {
				rockchip,pins = <0 RK_PB7 14 &pcfg_pull_none>;
			};
			/omit-if-no-ref/
			rm_io16_spi0_miso: rm-io16-spi0-miso {
				rockchip,pins = <0 RK_PC0 14 &pcfg_pull_none>;
			};
			/omit-if-no-ref/
			rm_io17_spi0_mosi: rm-io17-spi0-mosi {
				rockchip,pins = <0 RK_PC1 14 &pcfg_pull_none>;
			};
		};
		mclk_hzhy {
			/omit-if-no-ref/
			rm_io8_sai1_mclk: rm-io8-sai1-mclk {
				rockchip,pins = <0 RK_PB0 1 &pcfg_pull_none>;
			};
		};
		pwm0_ch3_hzhy {
			/omit-if-no-ref/
			rm_io6_pwm0_ch3: rm-io6-pwm0-ch3 {
				rockchip,pins = <0 RK_PA6 4 &pcfg_pull_none>;
			};
		};
};
